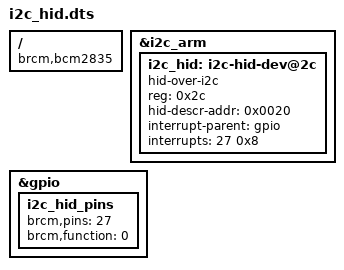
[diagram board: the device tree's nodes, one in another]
/dts-v1/;
/plugin/;

/{
	compatible = "brcm,bcm2835", "brcm,bcm2708", "brcm,bcm2709";

    /*
     i2c_arm == i2c1 on RP4
     dtparam=i2c_arm=on 
    */


	fragment@0 {
		target = <&i2c_arm>;
		__overlay__ {
			status = "okay";
		};
	};
	
    fragment@1 {
		target = <&gpio>;
		__overlay__ {
			i2c_hid_pins: i2c_hid_pins {
				brcm,pins = <27>;
				brcm,function = <0>;
			};
		};
	};

    
    fragment@2 {
        target = <&i2c_arm>;
        __overlay__ {
            #address-cells = <1>;
			#size-cells = <0>;
			i2c_hid: i2c-hid-dev@2c {
				compatible = "hid-over-i2c";
                reg = <0x2c>;
                
                
				hid-descr-addr = <0x0020>;
				interrupt-parent = <&gpio>;
				interrupts = <27 0x8>; //0x8 means it high active
                status = "okay";
			};
        };
    };

    __overrides__ {
        gpiopin = <&i2c_hid_pins>, "brcm,pins:0",
                    <&i2c_hid>, "interrupts:0";
        addr = <&i2c_hid>, "reg:0";
    };
};

/*
Device is 0x2c
HID descriptor 0x20
*/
